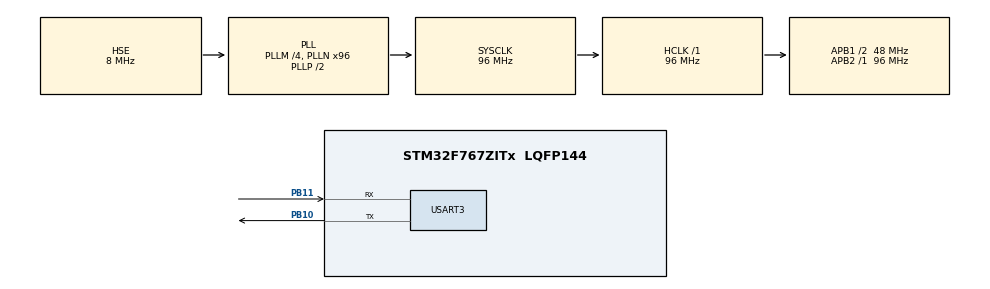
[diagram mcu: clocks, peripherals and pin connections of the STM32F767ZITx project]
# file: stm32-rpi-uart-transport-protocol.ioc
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Mcu.Family=STM32F7
Mcu.Name=STM32F767ZITx
Mcu.Package=LQFP144
NVIC.PriorityGroup=NVIC_PRIORITYGROUP_4
NVIC.USART3_IRQn=true\:0\:0\:false\:false\:true\:true\:true\:true
PB10.Mode=Asynchronous
PB10.Signal=USART3_TX
PB11.Mode=Asynchronous
PB11.Signal=USART3_RX
PH0/OSC_IN.Mode=HSE-External-Oscillator
PH0/OSC_IN.Signal=RCC_OSC_IN
PH1/OSC_OUT.Mode=HSE-External-Oscillator
PH1/OSC_OUT.Signal=RCC_OSC_OUT
ProjectManager.HeapSize=0x200
ProjectManager.StackSize=0x400
ProjectManager.TargetToolchain=STM32CubeIDE
RCC.48MHZClocksFreq_Value=24000000
RCC.AHBFreq_Value=96000000
RCC.APB1CLKDivider=RCC_HCLK_DIV2
RCC.APB1Freq_Value=48000000
RCC.APB1TimFreq_Value=96000000
RCC.APB2Freq_Value=96000000
RCC.APB2TimFreq_Value=96000000
RCC.CortexFreq_Value=96000000
RCC.HCLKFreq_Value=96000000
RCC.HSE_VALUE=8000000
RCC.HSI_VALUE=16000000
RCC.PLLM=4
RCC.PLLMUL=RCC_PLL_MUL9
RCC.PLLN=96
RCC.PLLQ=4
RCC.PLLSourceVirtual=RCC_PLLSOURCE_HSE
RCC.PRESCALERUSB=RCC_USBCLKSOURCE_PLL_DIV1_5
RCC.SYSCLKFreq_VALUE=96000000
RCC.SYSCLKSource=RCC_SYSCLKSOURCE_PLLCLK
RCC.SYSCLKSourceVirtual=RCC_SYSCLKSOURCE_PLLCLK
RCC.USBFreq_Value=48000000
RCC.VCOOutputFreq_Value=192000000
USART3.VirtualMode-Asynchronous=VM_ASYNC
board=NUCLEO-F767ZI

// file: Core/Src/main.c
/* USER CODE BEGIN Header */
/**
  ******************************************************************************
  * @file           : main.c
  * @brief          : STM32F767 ↔ RPi5 UART Transport Protocol v0.5.0 (USART3)
  ******************************************************************************
  * Protocol v2: <STX>TYPE|NODE|SEQ|DATA|CHK<ETX>
  * - STX = 0x02, ETX = 0x03
  * - CHK = XOR over ASCII bytes of "TYPE|NODE|SEQ|DATA"
  *
  * Telemetry frames use auto-incrementing SEQ.
  * Replies to HOST commands echo the HOST SEQ so the Pi can match responses.
  ******************************************************************************
  * @attention
  *
  * Copyright (c) 2026 STMicroelectronics.
  * All rights reserved.
  *
  * This software is licensed under terms that can be found in the LICENSE file
  * in the root directory of this software component.
  * If no LICENSE file comes with this software, it is provided AS-IS.
  *
  ******************************************************************************
  */
/* USER CODE END Header */
#include "main.h"
#include "string.h"
#include "stdio.h"
#include <stdlib.h>   // strtoul(), atoi()

UART_HandleTypeDef huart3;

void SystemClock_Config(void);
static void MX_GPIO_Init(void);
static void MX_USART3_UART_Init(void);

/* USER CODE BEGIN 0 */

/* ========= Protocol Settings ========= */
#define STX 0x02
#define ETX 0x03

#define RX_BUFFER_SIZE 192
#define TX_PAYLOAD_SIZE 256
#define TX_FRAME_SIZE   320

/* ========= Node Identity ========= */
static char NODE_ID[16] = "BUS01";
static char ROUTE_ID[16] = "25B";
static int  CURRENT_ETA = 3;

/* Latest TfL summary received from Raspberry Pi (for future display in v0.5.0) */
static char latest_tfl_summary[128] = {0};

/* ========= UART RX State =========
 * - We read 1 byte at a time in interrupt mode.
 * - When STX is received, we start buffering until ETX.
 * - On ETX, rx_buffer becomes a null-terminated string "TYPE|NODE|SEQ|DATA|CHK"
 */
static uint8_t rx_byte;
static char rx_buffer[RX_BUFFER_SIZE];
static uint16_t rx_index = 0;
static uint8_t receiving = 0;

/* ========= UART TX Sequence ========= */
static uint8_t tx_seq = 0;

/* ========= Duplicate detection for HOST commands =========
 * - If the host retries the same SEQ, we resend our last reply frame.
 */
static uint8_t last_host_seq = 255;

/* ========= Last Reply Storage (for duplicate HOST SEQ resend) ========= */
static char     last_reply_frame[TX_FRAME_SIZE];
static uint16_t last_reply_len = 0;

/* ========= Timing ========= */
static uint32_t last_hb_ms = 0;
static uint32_t last_arr_ms = 0;
static uint32_t last_dl_ms = 0;
static uint32_t last_tfl_ms = 0;

/* Forward declarations */
static uint8_t checksum_xor(const char *data);
static void send_packet_auto(const char *type, const char *node, const char *data);
static void handle_complete_message(const char *msg);
static void send_packet_reply_store(const char *type, const char *node, uint8_t seq, const char *data);

/**
 * @brief XOR checksum over ASCII payload bytes.
 * @param data Null-terminated payload string.
 */

static uint8_t checksum_xor(const char *data)
{
    uint8_t chk = 0;
    while (*data)
    {
        chk ^= (uint8_t)(*data);
        data++;
    }
    return chk;
}

/**
 * @brief Send a framed packet with auto-incrementing SEQ.
 *        Used for telemetry (HB/ARR/DL) and general messages not tied to a host command.
 */

static void send_packet_auto(const char *type, const char *node, const char *data)
{
    char payload[TX_PAYLOAD_SIZE];
    char frame[TX_FRAME_SIZE];

    uint8_t seq = tx_seq++;  // Global sequence for every TX frame (telemetry etc.)

    // Build: TYPE|NODE|SEQ|DATA
    int n = snprintf(payload, sizeof(payload), "%s|%s|%u|%s", type, node, seq, data);
    if (n < 0 || n >= (int)sizeof(payload)) return;

    uint8_t chk = checksum_xor(payload);

    // Build: <STX>payload|CHK<ETX>
    n = snprintf(frame, sizeof(frame), "%c%s|%02X%c", STX, payload, chk, ETX);
    if (n < 0 || n >= (int)sizeof(frame)) return;

    HAL_UART_Transmit(&huart3, (uint8_t*)frame, (uint16_t)n, HAL_MAX_DELAY);
}

/**
 * @brief Send a framed reply that echoes HOST SEQ.
 *        This is REQUIRED for host ACK/STATUS matching and retry logic.
 */
//static void send_packet_reply(const char *type, const char *node, uint8_t seq, const char *data)
//{
//    char payload[128];
//    char frame[160];
//
//    int n = snprintf(payload, sizeof(payload), "%s|%s|%u|%s", type, node, seq, data);
//    if (n < 0 || n >= (int)sizeof(payload)) return;
//
//    uint8_t chk = checksum_xor(payload);
//
//    n = snprintf(frame, sizeof(frame), "%c%s|%02X%c", STX, payload, chk, ETX);
//    if (n < 0 || n >= (int)sizeof(frame)) return;
//
//    HAL_UART_Transmit(&huart3, (uint8_t*)frame, (uint16_t)strlen(frame), HAL_MAX_DELAY);
//}

/* Send host replies (ACK/STATUS/ERR) echoing host SEQ, and store last reply for retry-resend.
 *
 * IMPORTANT:
 * This function may be called from the UART RX interrupt path (via handle_complete_message()).
 * For a demo/prototype it is OK, but for production you should avoid blocking UART TX inside IRQ.
 * Upgrade path: queue reply + transmit from main loop or use DMA/IT TX.
 */
static void send_packet_reply_store(const char *type, const char *node, uint8_t seq, const char *data)
{
    char payload[TX_PAYLOAD_SIZE];
    char frame[TX_FRAME_SIZE];

    int n = snprintf(payload, sizeof(payload), "%s|%s|%u|%s", type, node, seq, data);
    if (n < 0 || n >= (int)sizeof(payload)) return;

    uint8_t chk = checksum_xor(payload);

    n = snprintf(frame, sizeof(frame), "%c%s|%02X%c", STX, payload, chk, ETX);
    if (n < 0 || n >= (int)sizeof(frame)) return;

    /* Store last reply so duplicates can be answered */
//    strncpy(last_reply_frame, frame, sizeof(last_reply_frame) - 1);
//    last_reply_frame[sizeof(last_reply_frame) - 1] = '\0';
//    last_reply_len = (uint16_t)strlen(last_reply_frame);

    // cleaner version of the above ^^
    memcpy(last_reply_frame, frame, (size_t)n);
    last_reply_frame[n] = '\0';
    last_reply_len = (uint16_t)n;

    HAL_UART_Transmit(&huart3, (uint8_t*)last_reply_frame, last_reply_len, HAL_MAX_DELAY);
}

/* Parse a complete message (no STX/ETX), validate checksum, then dispatch command.
 *
 * Expected input string:
 *   TYPE|NODE|SEQ|DATA|CHK
 *
 * DATA may include additional separators in future; we split checksum from the end first.
 */

static void handle_complete_message(const char *msg)
{
    char copy[RX_BUFFER_SIZE];
    strncpy(copy, msg, sizeof(copy) - 1);
    copy[sizeof(copy) - 1] = '\0';

    // Split checksum from the end: "...|CHK"
    char *last_bar = strrchr(copy, '|');
    if (!last_bar) {
        send_packet_auto("ERR", NODE_ID, "FORMAT");
        return;
    }

    char *chk_str = last_bar + 1;
    *last_bar = '\0'; // now copy = "TYPE|NODE|SEQ|DATA"

    uint8_t calc_chk = checksum_xor(copy);
    uint8_t recv_chk = (uint8_t)strtoul(chk_str, NULL, 16);

    if (calc_chk != recv_chk) {
        send_packet_auto("ERR", NODE_ID, "CHK");
        return;
    }

    // Parse first fields: TYPE|NODE|SEQ|DATA(rest)
    char *type    = strtok(copy, "|");
    char *node    = strtok(NULL, "|");
    char *seq_str = strtok(NULL, "|");
    char *data    = strtok(NULL, ""); // remainder as DATA

    if (!type || !node || !seq_str || !data) {
        send_packet_auto("ERR", NODE_ID, "FORMAT");
        return;
    }

    uint8_t host_seq = (uint8_t)atoi(seq_str);

    if (strcmp(type, "CMD") == 0) {
        if (host_seq == last_host_seq) {
        	/* Retry support: host retried same SEQ -> re-send last stored reply */
            if (last_reply_len > 0) {
                HAL_UART_Transmit(&huart3, (uint8_t*)last_reply_frame, last_reply_len, HAL_MAX_DELAY);
            }
            return;
        }
        last_host_seq = host_seq;
    }

    // Only accept commands from host
    if (strcmp(type, "CMD") == 0)
    {
        (void)node; // node is "HOST" typically; not required for this demo

        if (strcmp(data, "PING") == 0) {
            send_packet_reply_store("ACK", NODE_ID, host_seq, "PONG");
        }
        else if (strcmp(data, "STATUS") == 0) {
            char info[96];
            snprintf(info, sizeof(info), "NODE=%s,ROUTE=%s,ETA=%d", NODE_ID, ROUTE_ID, CURRENT_ETA);
            send_packet_reply_store("STATUS", NODE_ID, host_seq, info);
        }
        else if (strncmp(data, "SETROUTE=", 9) == 0) {
            strncpy(ROUTE_ID, data + 9, sizeof(ROUTE_ID) - 1);
            ROUTE_ID[sizeof(ROUTE_ID) - 1] = '\0';
            send_packet_reply_store("ACK", NODE_ID, host_seq, "ROUTE_SET");
        }
        else if (strncmp(data, "SETETA=", 7) == 0) {
            CURRENT_ETA = atoi(data + 7);
            send_packet_reply_store("ACK", NODE_ID, host_seq, "ETA_SET");
        }
        else if (strncmp(data, "TFL=", 4) == 0)
        {
            /* v0.5.0: Host sends compact real-time TfL summary (already formatted on Pi) */
            strncpy(latest_tfl_summary, data + 4, sizeof(latest_tfl_summary) - 1);
            latest_tfl_summary[sizeof(latest_tfl_summary) - 1] = '\0';

            send_packet_reply_store("ACK", NODE_ID, host_seq, "TFL_RX");
        }
        else if (strcmp(data, "GETTFL") == 0)
        {
            char out[TX_PAYLOAD_SIZE];

            if (latest_tfl_summary[0] == '\0')
            {
                snprintf(out, sizeof(out), "TFL=NONE");
            }
            else
            {
                snprintf(out, sizeof(out), "TFL=%s", latest_tfl_summary);
            }

            send_packet_reply_store("STATUS", NODE_ID, host_seq, out);
        }
        else
        {
            send_packet_reply_store("ERR", NODE_ID, host_seq, "UNKNOWN_CMD");
        }
    }
    else {
        // Ignore unknown types quietly OR respond with error (your choice)
        // send_packet_auto("ERR", NODE_ID, "UNKNOWN_TYPE");
    }
}

/* USER CODE END 0 */

int main(void)
{

  /* MCU Configuration--------------------------------------------------------*/

  /* Reset of all peripherals, Initializes the Flash interface and the Systick. */
  HAL_Init();

  /* Configure the system clock */
  SystemClock_Config();

  /* Initialize all configured peripherals */
  MX_GPIO_Init();
  MX_USART3_UART_Init();
  /* USER CODE BEGIN 2 */

  /* Start interrupt-driven RX (1 byte at a time) */
  HAL_UART_Receive_IT(&huart3, &rx_byte, 1);

  /* Initialize timers */
  uint32_t now = HAL_GetTick();
  last_hb_ms  = now;
  last_arr_ms = now;
  last_dl_ms  = now;
  last_tfl_ms = now;
  /* USER CODE END 2 */

  /* Infinite loop */
  while (1)
  {
	    /* USER CODE BEGIN 3 */
      uint32_t t = HAL_GetTick();

      /* Heartbeat every 5 seconds */
      if ((t - last_hb_ms) >= 5000)
      {
          last_hb_ms = t;
          send_packet_auto("HB", NODE_ID, "OK");
      }

      /* Arrival update every 10 seconds */
      if ((t - last_arr_ms) >= 10000)
      {
          last_arr_ms = t;

          char data[96];
          snprintf(data, sizeof(data), "ROUTE=%s,STOP=STOP12,ETA=%d", ROUTE_ID, CURRENT_ETA);
          send_packet_auto("ARR", NODE_ID, data);
      }

      /* Delay event every 30 seconds */
      if ((t - last_dl_ms) >= 30000)
      {
          last_dl_ms = t;
          send_packet_auto("DL", NODE_ID, "+5MIN");
      }

      /* Broadcast TfL summary every 15 seconds */
      if ((t - last_tfl_ms) >= 15000)
      {
          last_tfl_ms = t;

          if (latest_tfl_summary[0] != '\0')
          {
              send_packet_auto("TFL", NODE_ID, latest_tfl_summary);
          }
      }

	    /* Main loop stays free; RX handled in interrupt callback */

    /* USER CODE BEGIN 3 */
  }
  /* USER CODE END 3 */
}

void SystemClock_Config(void)
{
  RCC_OscInitTypeDef RCC_OscInitStruct = {0};
  RCC_ClkInitTypeDef RCC_ClkInitStruct = {0};

  /** Configure the main internal regulator output voltage
  */
  __HAL_RCC_PWR_CLK_ENABLE();
  __HAL_PWR_VOLTAGESCALING_CONFIG(PWR_REGULATOR_VOLTAGE_SCALE3);

  /** Initializes the RCC Oscillators according to the specified parameters
  * in the RCC_OscInitTypeDef structure.
  */
  RCC_OscInitStruct.OscillatorType = RCC_OSCILLATORTYPE_HSE;
  RCC_OscInitStruct.HSEState = RCC_HSE_ON;
  RCC_OscInitStruct.PLL.PLLState = RCC_PLL_ON;
  RCC_OscInitStruct.PLL.PLLSource = RCC_PLLSOURCE_HSE;
  RCC_OscInitStruct.PLL.PLLM = 4;
  RCC_OscInitStruct.PLL.PLLN = 96;
  RCC_OscInitStruct.PLL.PLLP = RCC_PLLP_DIV2;
  RCC_OscInitStruct.PLL.PLLQ = 4;
  RCC_OscInitStruct.PLL.PLLR = 2;
  if (HAL_RCC_OscConfig(&RCC_OscInitStruct) != HAL_OK)
  {
    Error_Handler();
  }

  /** Activate the Over-Drive mode
  */
  if (HAL_PWREx_EnableOverDrive() != HAL_OK)
  {
    Error_Handler();
  }

  /** Initializes the CPU, AHB and APB buses clocks
  */
  RCC_ClkInitStruct.ClockType = RCC_CLOCKTYPE_HCLK|RCC_CLOCKTYPE_SYSCLK
                              |RCC_CLOCKTYPE_PCLK1|RCC_CLOCKTYPE_PCLK2;
  RCC_ClkInitStruct.SYSCLKSource = RCC_SYSCLKSOURCE_PLLCLK;
  RCC_ClkInitStruct.AHBCLKDivider = RCC_SYSCLK_DIV1;
  RCC_ClkInitStruct.APB1CLKDivider = RCC_HCLK_DIV2;
  RCC_ClkInitStruct.APB2CLKDivider = RCC_HCLK_DIV1;

  if (HAL_RCC_ClockConfig(&RCC_ClkInitStruct, FLASH_LATENCY_3) != HAL_OK)
  {
    Error_Handler();
  }
}

static void MX_USART3_UART_Init(void)
{

  huart3.Instance = USART3;
  huart3.Init.BaudRate = 115200;
  huart3.Init.WordLength = UART_WORDLENGTH_8B;
  huart3.Init.StopBits = UART_STOPBITS_1;
  huart3.Init.Parity = UART_PARITY_NONE;
  huart3.Init.Mode = UART_MODE_TX_RX;
  huart3.Init.HwFlowCtl = UART_HWCONTROL_NONE;
  huart3.Init.OverSampling = UART_OVERSAMPLING_16;
  huart3.Init.OneBitSampling = UART_ONE_BIT_SAMPLE_DISABLE;
  huart3.AdvancedInit.AdvFeatureInit = UART_ADVFEATURE_NO_INIT;
  if (HAL_UART_Init(&huart3) != HAL_OK)
  {
    Error_Handler();
  }

}

static void MX_GPIO_Init(void)
{
/* USER CODE BEGIN MX_GPIO_Init_1 */
   GPIO_InitTypeDef GPIO_InitStruct = {0};
/* USER CODE END MX_GPIO_Init_1 */

  /* GPIO Ports Clock Enable */
  __HAL_RCC_GPIOH_CLK_ENABLE();
  __HAL_RCC_GPIOB_CLK_ENABLE();
  __HAL_RCC_USART3_CLK_ENABLE();

/* USER CODE BEGIN MX_GPIO_Init_2 */
  /* USART3 TX PB10 */
  GPIO_InitStruct.Pin = GPIO_PIN_10;
  GPIO_InitStruct.Mode = GPIO_MODE_AF_PP;
  GPIO_InitStruct.Pull = GPIO_PULLUP;
  GPIO_InitStruct.Speed = GPIO_SPEED_FREQ_VERY_HIGH;
  GPIO_InitStruct.Alternate = GPIO_AF7_USART3;
  HAL_GPIO_Init(GPIOB, &GPIO_InitStruct);

  /* USART3 RX PB11 */
  GPIO_InitStruct.Pin = GPIO_PIN_11;
  GPIO_InitStruct.Mode = GPIO_MODE_AF_PP;
  GPIO_InitStruct.Pull = GPIO_PULLUP;
  GPIO_InitStruct.Alternate = GPIO_AF7_USART3;
  HAL_GPIO_Init(GPIOB, &GPIO_InitStruct);
/* USER CODE BEGIN MX_GPIO_Init_2 */
/* USER CODE END MX_GPIO_Init_2 */
}

/* USER CODE BEGIN 4 */
/**
 * @brief UART RX complete callback (interrupt-driven).
 *
 * RX state machine:
 * - STX starts a new frame
 * - bytes appended into rx_buffer
 * - ETX ends the frame => null-terminate => handle_complete_message()
 *
 * Note:
 * - This implementation parses in IRQ context (simple + OK for prototype).
 * - For production, consider deferring parsing to main loop (set a flag / queue).
 */
void HAL_UART_RxCpltCallback(UART_HandleTypeDef *huart)
{
    if (huart->Instance == USART3)
    {
        if (rx_byte == STX)
        {
            receiving = 1;
            rx_index = 0;
        }
        else if ((rx_byte == ETX) && receiving)
        {
            rx_buffer[rx_index] = '\0';
            receiving = 0;

            handle_complete_message(rx_buffer);

            rx_index = 0;
        }
        else if (receiving)
        {
            if (rx_index < (RX_BUFFER_SIZE - 1))
            {
                rx_buffer[rx_index++] = (char)rx_byte;
            }
            else
            {
                receiving = 0;
                rx_index = 0;
                send_packet_auto("ERR", NODE_ID, "RX_OVERFLOW");
            }
        }

        /* Re-arm RX interrupt */
        HAL_UART_Receive_IT(&huart3, &rx_byte, 1);
    }
}

/* USER CODE END 4 */

void Error_Handler(void)
{
  __disable_irq();
  while (1)
  {
  }
}
